# R7FA6T2BD register map
Vendor: Renesas Electronics Corporation; Series: RA6; File version: 1.40.00
CPU: CM33 r0p4, little endian, MPU, FPU, VTOR, 4 interrupt priority bits, 96 interrupts
Registers are 32-bit, read-write, reset 0x0 unless marked. A register's access mark holds for its fields unless they carry their own. Offsets are from the block's base; [hi:lo] are bit positions; {n}, {i} and the like mark numbered series.

## IIC_B0 — Inter,Integrated Circuit 0
Base 0x4011F000
Same registers: IIC_B1 0x4011F400
0x14 BCTL — Bus Control Register
  [31] BUSE — Bus Enable
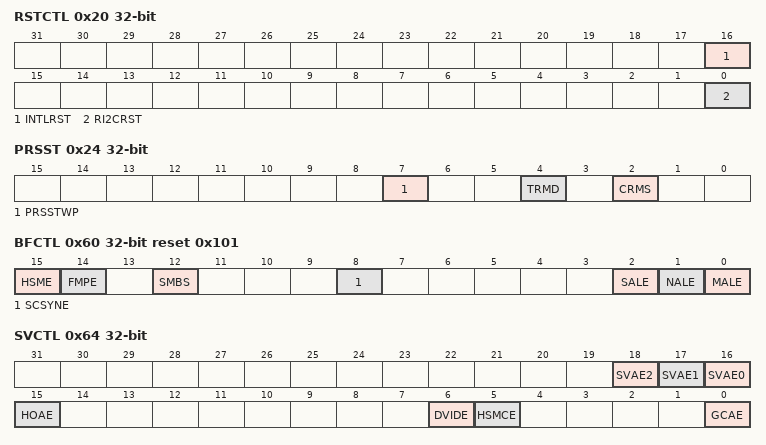
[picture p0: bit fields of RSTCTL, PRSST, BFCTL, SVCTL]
0x20 RSTCTL — Reset Control Register
  [16] INTLRST — Internal Software Reset
  [0] RI2CRST — IIC Software Reset
0x24 PRSST — Present State Register
  [7] PRSSTWP wo — Present State Write Protect
  [4] TRMD ro — Transmit/Receive Mode
  [2] CRMS — Current Master
0x60 BFCTL reset 0x101 — Bus Function Control Register
  [15] HSME — High Speed Mode Enable
  [14] FMPE — Fast,mode Plus Enable
  [12] SMBS — SMBus/I2C Bus Selection
  [8] SCSYNE — SCL Synchronous Circuit Enable
  [2] SALE — Slave Arbitration,Lost Detection Enable
  [1] NALE — NACK Transmission Arbitration,Lost Detection Enable
  [0] MALE — Master Arbitration,Lost Detection Enable
0x64 SVCTL — Slave Control Register
  [18] SVAE2 — Slave Address Enable 2
  [17] SVAE1 — Slave Address Enable 1
  [16] SVAE0 — Slave Address Enable 0
  [15] HOAE — Host Address Enable
  [6] DVIDE — Device,ID Address Enable
  [5] HSMCE — Hs,mode Master Code Enable
  [0] GCAE — General Call Address Enable
0x70 REFCKCTL — Reference Clock Control Register
  [2:0] IREFCKS — Internal Reference Clock Selection
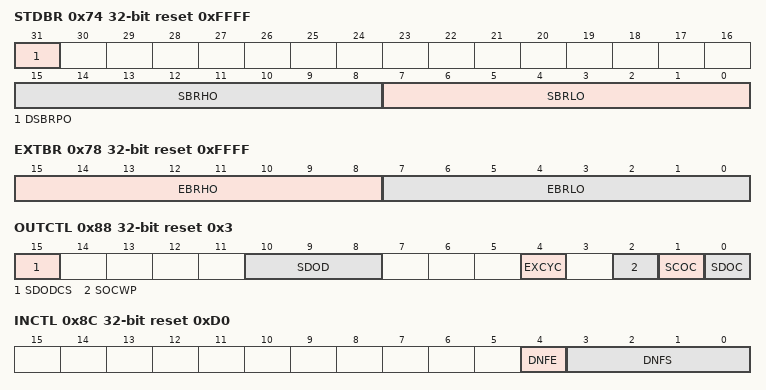
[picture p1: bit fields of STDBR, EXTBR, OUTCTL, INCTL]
0x74 STDBR reset 0xFFFF — Standard Bit Rate Register
  [31] DSBRPO — Double the Standard Bit Rate Period for Open,Drain
  [15:8] SBRHO — Count value of the High,level period of SCL clock
  [7:0] SBRLO — Count value of the Low,level period of SCL clock
0x78 EXTBR reset 0xFFFF — Extended Bit Rate Register
  [15:8] EBRHO — Extended Bit Rate High,Level Period Open,Drain
  [7:0] EBRLO — Extended Bit Rate Low,Level Period Open,Drain
0x7C BFRECDT — Bus Free Condition Detection Time Register
  [8:0] FRECYC — Bus Free Condition Detection Cycle
0x88 OUTCTL reset 0x3 — Output Control Register
  [15] SDODCS — SDA Output Delay Clock Source Selection
  [10:8] SDOD — SDA Output Delay
  [4] EXCYC — Extra SCL Clock Cycle Output
  [2] SOCWP wo — SCL/SDA Output Control Write Protect
  [1] SCOC — SCL Output Control
  [0] SDOC — SDA Output Control
0x8C INCTL reset 0xD0 — Input Control Register
  [4] DNFE — Digital Noise Filter Circuit Enable
  [3:0] DNFS — Digital Noise Filter Stage Selection
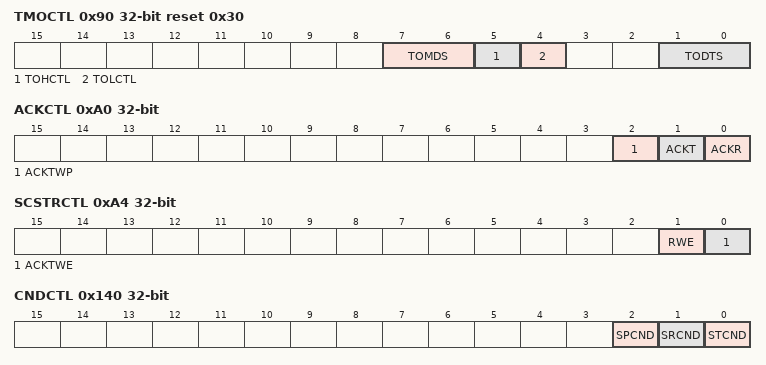
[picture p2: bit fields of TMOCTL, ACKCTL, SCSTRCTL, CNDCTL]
0x90 TMOCTL reset 0x30 — Timeout Control Register
  [7:6] TOMDS — Timeout Operation Mode Selection
  [5] TOHCTL — Timeout H Count Control
  [4] TOLCTL — Timeout L Count Control
  [1:0] TODTS — Timeout Detection Time Selection
0xA0 ACKCTL — Acknowledge Control Register
  [2] ACKTWP wo — ACKT Write Protect
  [1] ACKT — Acknowledge Transmission
  [0] ACKR ro — Acknowledge Reception
0xA4 SCSTRCTL — SCL Stretch Control Register
  [1] RWE — Receive Wait Enable
  [0] ACKTWE — Acknowledge Transmission Wait Enable
0x140 CNDCTL — Condition Control Register
  [2] SPCND — STOP (P) Condition Issuance
  [1] SRCND — Repeated START (Sr) Condition Issuance
  [0] STCND — START (S) Condition Issuance
0x158 NTDTBP0 — Normal Transfer Data Buffer Port Register 0
0x158 NTDTBP0_BY 8-bit (alternate view of NTDTBP0) — Normal Transfer Data Buffer Port Register 0
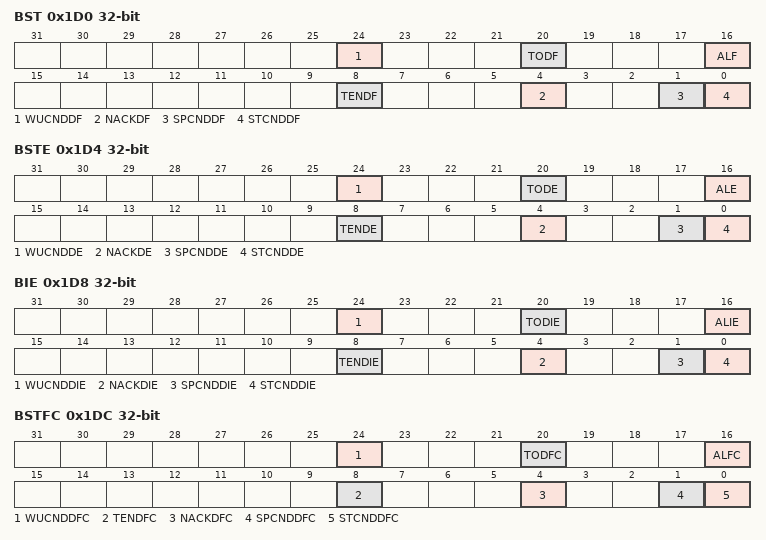
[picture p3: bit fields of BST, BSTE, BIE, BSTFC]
0x1D0 BST — Bus Status Register
  [24] WUCNDDF — Wake,Up Condition Detection Flag
  [20] TODF — Timeout Detection Flag
  [16] ALF — Arbitration Lost Flag
  [8] TENDF — Transmit End Flag
  [4] NACKDF — NACK Detection Flag
  [1] SPCNDDF — STOP Condition Detection Flag
  [0] STCNDDF — START Condition Detection Flag
0x1D4 BSTE — Bus Status Enable Register
  [24] WUCNDDE — Wake,up Condition Detection Enable
  [20] TODE — Timeout Detection Enable
  [16] ALE — Arbitration Lost Enable
  [8] TENDE — Transmit End Enable
  [4] NACKDE — NACK Detection Enable
  [1] SPCNDDE — STOP Condition Detection Enable
  [0] STCNDDE — START Condition Detection Enable
0x1D8 BIE — Bus Interrupt Enable Register
  [24] WUCNDDIE — Wake,Up Condition Detection Interrupt Enable
  [20] TODIE — Timeout Detection Interrupt Enable
  [16] ALIE — Arbitration Lost Interrupt Enable
  [8] TENDIE — Transmit End Interrupt Enable
  [4] NACKDIE — NACK Detection Interrupt Enable
  [1] SPCNDDIE — STOP Condition Detection Interrupt Enable
  [0] STCNDDIE — START Condition Detection Interrupt Enable
0x1DC BSTFC — Bus Status Force Register
  [24] WUCNDDFC wo — Wake,Up Condition Detection Force
  [20] TODFC wo — Timeout Detection Force
  [16] ALFC wo — Arbitration Lost Force
  [8] TENDFC wo — Transmit End Force
  [4] NACKDFC wo — NACK Detection Force
  [1] SPCNDDFC wo — STOP condition Detection Force
  [0] STCNDDFC wo — START condition Detection Force
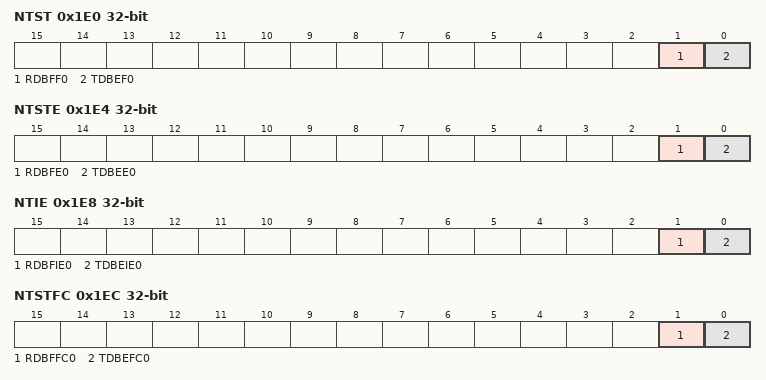
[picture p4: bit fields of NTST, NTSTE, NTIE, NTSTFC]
0x1E0 NTST — Normal Transfer Status Register
  [1] RDBFF0 — Normal Receive Data Buffer Full Flag 0
  [0] TDBEF0 — Normal Transmit Data Buffer Empty Flag 0
0x1E4 NTSTE — Normal Transfer Status Enable Register
  [1] RDBFE0 — Normal Receive Data Buffer Full Enable 0
  [0] TDBEE0 — Normal Transmit Data Buffer Empty Enable 0
0x1E8 NTIE — Normal Transfer Interrupt Enable Register
  [1] RDBFIE0 — Normal Receive Data Buffer Full Interrupt Enable 0
  [0] TDBEIE0 — Normal Transmit Data Buffer Empty Interrupt Enable 0
0x1EC NTSTFC wo — Normal Transfer Status Force Register
  [1] RDBFFC0 — Normal Receive Data Buffer Full Force 0
  [0] TDBEFC0 — Normal Transmit Data Buffer Empty Force 0
0x210 BCST ro — Bus Condition Status Register
  [0] BFREF — Bus Free Detection Flag
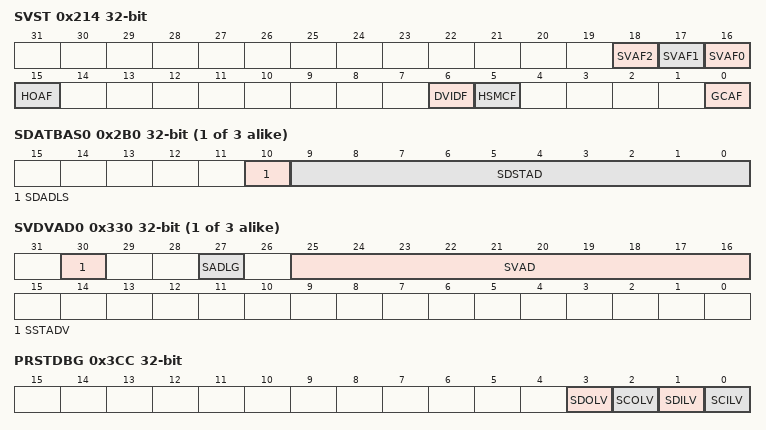
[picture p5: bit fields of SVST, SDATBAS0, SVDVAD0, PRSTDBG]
0x214 SVST — Slave Status Register
  [18] SVAF2 — Slave Address Detection Flag 2
  [17] SVAF1 — Slave Address Detection Flag 1
  [16] SVAF0 — Slave Address Detection Flag 0
  [15] HOAF — Host Address Detection Flag
  [6] DVIDF — Device,ID Address Detection Flag
  [5] HSMCF — Hs,mode Master Code Detection Flag
  [0] GCAF — General Call Address Detection Flag
{0x2B0+4i} SDATBAS{i} (i=0..2) — Slave Device Address Table Basic Register {i}
  [10] SDADLS — Slave Device Address Length Selection
  [9:0] SDSTAD — Slave Device Static Address
{0x330+4i} SVDVAD{i} (i=0..2) ro — Slave Device Address Register {i}
  [30] SSTADV — Slave Static Address Valid
  [27] SADLG — Slave Address Length
  [25:16] SVAD — Slave Address
0x380 BITCNT ro — Bit Count Register
  [4:0] BCNT — Bit Counter
0x3CC PRSTDBG ro — Present State Debug Register
  [3] SDOLV — SDA Output Level
  [2] SCOLV — SCL Output Level
  [1] SDILV — SDA Line Signal Level
  [0] SCILV — SCL Line Signal Level
